# R7FA6T1 register map
Vendor: Renesas; Series: RA6; File version: 1.2
CPU: CM4 r0p1, little endian, MPU, FPU, VTOR, 4 interrupt priority bits
Registers are 8-bit, read-write, reset 0x0 unless marked. A register's access mark holds for its fields unless they carry their own. Offsets are from the block's base; [hi:lo] are bit positions; 'fields as' and 'values as' point back to an identical list.

## SRAM — SRAM Control
Base 0x40002000
0x00 PARIOAD — SRAM Parity Error Operation After Detection Register
  [0] OAD — Operation after Detection
    0=Non-maskable interrupt; 1=Reset
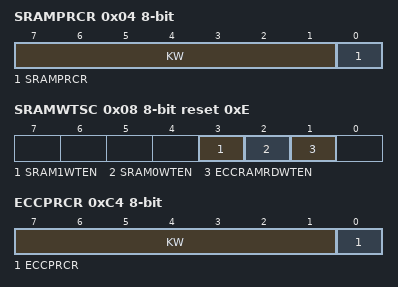
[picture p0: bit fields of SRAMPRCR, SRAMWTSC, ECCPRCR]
0x04 SRAMPRCR — SRAM Protection Register
  [7:1] KW wo — Write Key Code
    120=Writing to the RAMPRCR bit is valid, when the KEY bits are written 1111000b; other=others (Writing to the RAMPRCR bit is invalid.)
  [0] SRAMPRCR — Register Write Control
    0=Disable writes to protected registers; 1=Enable writes to protected registers
0x08 SRAMWTSC reset 0xE — RAM Wait State Control Register
  [3] SRAM1WTEN — SRAM1 Wait Enable
    0=Not add wait state in read access cycle to SRAM1; 1=Add wait state in read access cycle to SRAM1
  [2] SRAM0WTEN — SRAM0 Wait Enable
    0=Not add wait state in read access cycle to SRAM0; 1=Add wait state in read access cycle to SRAM0
  [1] ECCRAMRDWTEN — ECCRAM Read wait enable
    0=Not add wait state in read access cycle to SRAM0 (ECC area); 1=Add wait state in read access cycle to SRAM0 (ECC area)
0xC0 ECCMODE — ECCRAM Operating Mode Control Register
  [1:0] ECCMOD — ECC Operating Mode Select
    0=Disable ECC function; 1=Setting prohibited; 2=Enable ECC function without error checking; 3=Enable ECC function with error checking
0xC1 ECC2STS — ECCRAM 2-Bit Error Status Register
  [0] ECC2ERR write-0-clears read-modifies — ECC 2-Bit Error Status
    0=No 2-bit ECC error occurred; 1=2-bit ECC error occurred
0xC2 ECC1STSEN — ECCRAM 1-Bit Error Information Update Enable Register
  [0] E1STSEN — ECC 1-Bit Error Information Update Enable
    0=Disables updating of the 1-bit ECC error information; 1=Enables updating of the 1-bit ECC error information
0xC3 ECC1STS — ECCRAM 1-Bit Error Status Register
  [0] ECC1ERR write-0-clears read-modifies — ECC 1-Bit Error Status
    0=No 1-bit ECC error occurred; 1=1-bit ECC error occurred
0xC4 ECCPRCR — ECCRAM Protection Register
  [7:1] KW wo — Write Key Code
    120=Writing to the ECCRAMPRCR bit is valid, when the KEY bits are written 1111000b; other=others (Writing to the ECCRAMPRCR bit is invalid.)
  [0] ECCPRCR — ECCRAMETST Register Write Control
    values as SRAMPRCR.SRAMPRCR
0xD4 ECCETST — ECC Test Control Register
  [0] TSTBYP — ECC Bypass Select
    0=ECC bypass disabled; 1=ECC bypass enabled
0xD8 ECCOAD — RAM ECC Error Operation After Detection Register
  [0] OAD — Operation after Detection
    0=Non maskable interrupt; 1=Internal reset

## DMAC0 — Direct memory access controller 0
Base 0x40005000
Same registers: DMAC1 0x40005040, DMAC2 0x40005080, DMAC3 0x400050C0, DMAC4 0x40005100, DMAC5 0x40005140, DMAC6 0x40005180, DMAC7 0x400051C0
0x00 DMSAR 32-bit — DMA Source Address Register
  [31:0] DMSAR — Specifies the transfer source start address.
0x04 DMDAR 32-bit — DMA Destination Address Register
  [31:0] DMDAR — Specifies the transfer destination start address.
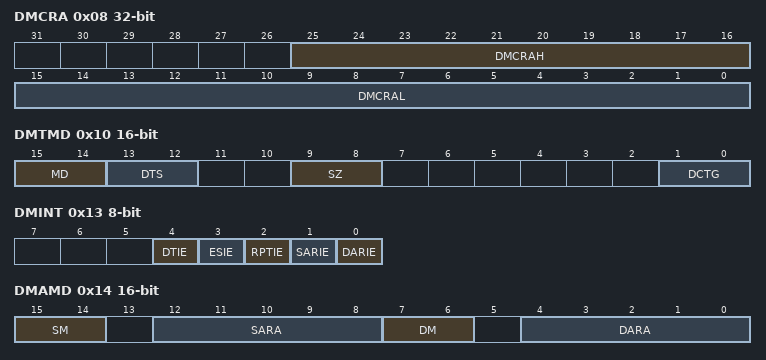
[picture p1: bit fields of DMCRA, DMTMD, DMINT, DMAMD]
0x08 DMCRA 32-bit — DMA Transfer Count Register
  [25:16] DMCRAH — Upper bits of transfer count
  [15:0] DMCRAL — Lower bits of transfer count
0x0C DMCRB 16-bit — DMA Block Transfer Count Register
  [15:0] DMCRB — Specifies the number of block transfer operations or repeat transfer operations.
    0=65,536 blocks; other=others (DMCRB blocks)
0x10 DMTMD 16-bit — DMA Transfer Mode Register
  [15:14] MD — Transfer Mode Select
    0=Normal transfer; 1=Repeat transfer; 2=Block transfer; 3=Setting prohibited
  [13:12] DTS — Repeat Area Select
    0=Specify destination as the repeat area or block area; 1=Specify source as the repeat area or block area; 2=Do not specify repeat area or block area; 3=Setting prohibited
  [9:8] SZ — Transfer Data Size Select
    0=8 bits; 1=16 bits; 2=32 bits; 3=Setting prohibited
  [1:0] DCTG — Transfer Request Source Select
    0=Software; 1=Interrupts from peripheral modules or external interrupt input pins; other=others (Setting prohibited)
0x13 DMINT — DMA Interrupt Setting Register
  [all] fields
    0=Disable; 1=Enable
  [4] DTIE — Transfer End Interrupt Enable
  [3] ESIE — Transfer Escape End Interrupt Enable
  [2] RPTIE — Repeat Size End Interrupt Enable
  [1] SARIE — Source Address Extended Repeat Area Overflow Interrupt Enable
  [0] DARIE — Destination Address Extended Repeat Area Overflow Interrupt Enable
0x14 DMAMD 16-bit — DMA Address Mode Register
  [15:14] SM — Source Address Update Mode
    0=Fixed address; 1=Offset addition; 2=Incremented address; 3=Decremented address
  [12:8] SARA — Source Address Extended Repeat Area Specifies the extended repeat area on the source address. For details on the settings.
  [7:6] DM — Destination Address Update Mode
    values as SM
  [4:0] DARA — Destination Address Extended Repeat Area Specifies the extended repeat area on the destination address. For details on the settings.
0x18 DMOFR 32-bit — DMA Offset Register
  [31:0] DMOFR — Specifies the offset when offset addition is selected as the address update mode for transfer source or destination.
0x1C DMCNT — DMA Transfer Enable Register
  [0] DTE read-modifies — DMA Transfer Enable
    0=Disable; 1=Enable
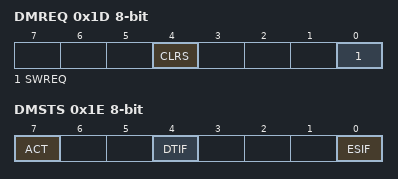
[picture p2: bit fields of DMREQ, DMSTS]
0x1D DMREQ — DMA Software Start Register
  [4] CLRS — DMA Software Start Bit Auto Clear Select
    0=Clear SWREQ bit after DMA transfer is started by software; 1=Do not clear SWREQ bit after DMA transfer is started by software
  [0] SWREQ read-modifies — DMA Software Start
    0=Do not request DMA transfer; 1=Request DMA transfer
0x1E DMSTS — DMAC Module Activation Register
  [7] ACT ro — DMA Active Flag
    0=DMAC operation is suspended; 1=DMAC is operating
  [4] DTIF write-0-clears read-modifies — Transfer End Interrupt Flag
    0=No interrupt occurred; 1=Interrupt occurred
  [0] ESIF write-0-clears read-modifies — Transfer Escape End Interrupt Flag
    0=A transfer escape end interrupt has not been generated; 1=A transfer escape end interrupt has been generated
